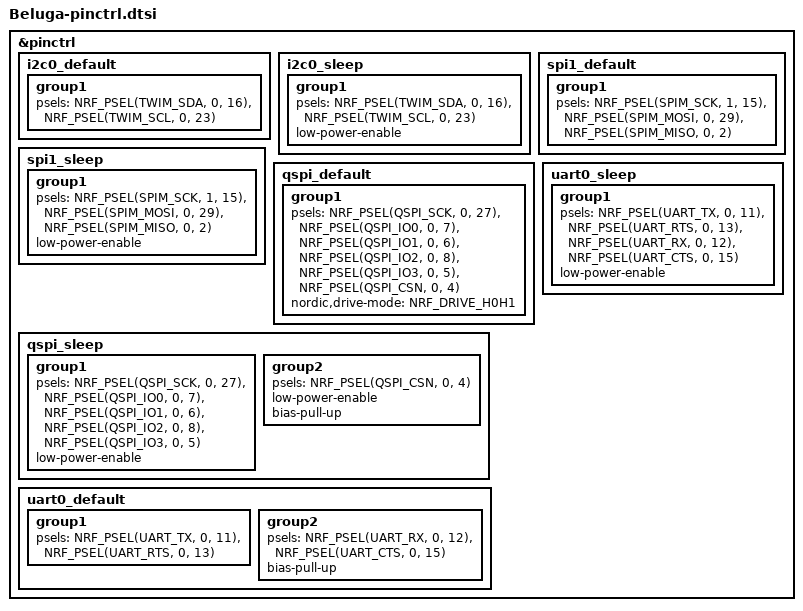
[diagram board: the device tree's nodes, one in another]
&pinctrl {
	i2c0_default: i2c0_default {
		group1 {
			psels = <NRF_PSEL(TWIM_SDA, 0, 16)>,
					<NRF_PSEL(TWIM_SCL, 0, 23)>;
		};
	};
	i2c0_sleep: i2c0_sleep {
		group1 {
			psels = <NRF_PSEL(TWIM_SDA, 0, 16)>,
					<NRF_PSEL(TWIM_SCL, 0, 23)>;
			low-power-enable;
		};
	};

	spi1_default: spi1_default {
		group1 {
			psels = <NRF_PSEL(SPIM_SCK, 1, 15)>,
					<NRF_PSEL(SPIM_MOSI, 0, 29)>,
					<NRF_PSEL(SPIM_MISO, 0, 2)>;
		};
	};
	spi1_sleep: spi1_sleep {
		group1 {
			psels = <NRF_PSEL(SPIM_SCK, 1, 15)>,
					<NRF_PSEL(SPIM_MOSI, 0, 29)>,
					<NRF_PSEL(SPIM_MISO, 0, 2)>;
			low-power-enable;
		};
	};

	qspi_default: qspi_default {
		group1 {
			psels = <NRF_PSEL(QSPI_SCK, 0, 27)>,
					<NRF_PSEL(QSPI_IO0, 0, 7)>,
					<NRF_PSEL(QSPI_IO1, 0, 6)>,
					<NRF_PSEL(QSPI_IO2, 0, 8)>,
					<NRF_PSEL(QSPI_IO3, 0, 5)>,
					<NRF_PSEL(QSPI_CSN, 0, 4)>;
			nordic,drive-mode = <NRF_DRIVE_H0H1>;
		};
	};

	qspi_sleep: qspi_sleep {
		group1 {
			psels = <NRF_PSEL(QSPI_SCK, 0, 27)>,
					<NRF_PSEL(QSPI_IO0, 0, 7)>,
					<NRF_PSEL(QSPI_IO1, 0, 6)>,
					<NRF_PSEL(QSPI_IO2, 0, 8)>,
					<NRF_PSEL(QSPI_IO3, 0, 5)>;
			low-power-enable;
		};
		group2 {
			psels = <NRF_PSEL(QSPI_CSN, 0, 4)>;
			low-power-enable;
			bias-pull-up;
		};
	};

	uart0_default: uart0_default {
		group1 {
			psels = <NRF_PSEL(UART_TX, 0, 11)>,
					<NRF_PSEL(UART_RTS, 0, 13)>;
		};
		group2 {
			psels = <NRF_PSEL(UART_RX, 0, 12)>,
					<NRF_PSEL(UART_CTS, 0, 15)>;
			bias-pull-up;
		};
	};
	uart0_sleep: uart0_sleep {
		group1 {
			psels = <NRF_PSEL(UART_TX, 0, 11)>,
					<NRF_PSEL(UART_RTS, 0, 13)>,
					<NRF_PSEL(UART_RX, 0, 12)>,
					<NRF_PSEL(UART_CTS, 0, 15)>;
			low-power-enable;
		};
	};
};
